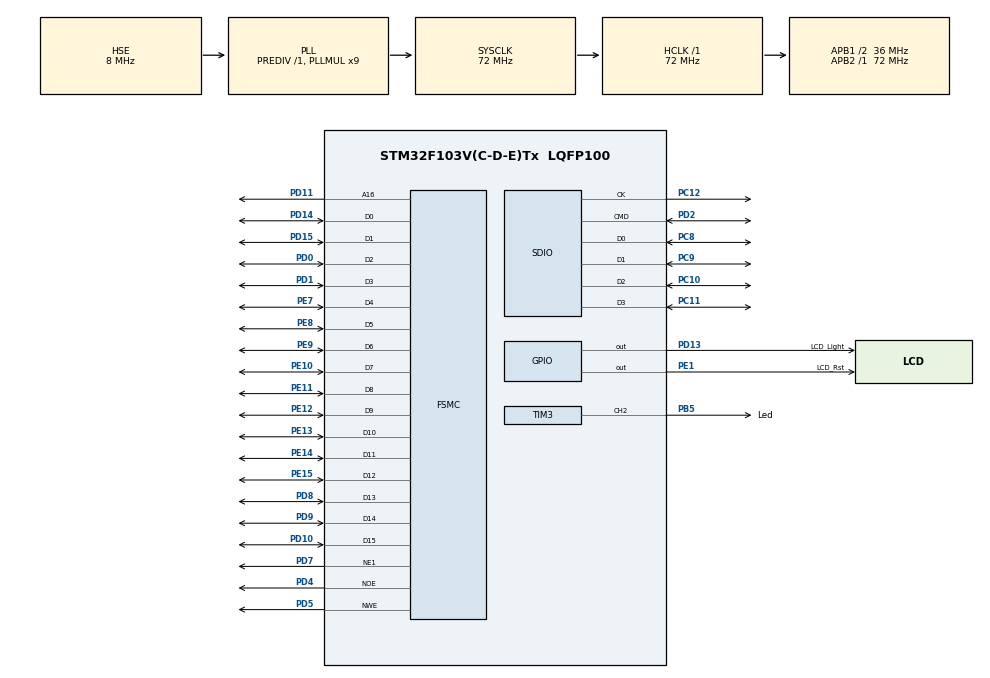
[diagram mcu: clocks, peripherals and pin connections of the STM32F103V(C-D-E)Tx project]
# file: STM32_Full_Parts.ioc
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FREERTOS.Tasks01=defaultTask,0,128,StartDefaultTask,Default,NULL
FREERTOS.configTOTAL_HEAP_SIZE=10000
FSMC.AddressSetupTime1=2
FSMC.BusTurnAroundDuration1=0
FSMC.DataSetupTime1=5
Mcu.Family=STM32F1
Mcu.Name=STM32F103V(C-D-E)Tx
Mcu.Package=LQFP100
NVIC.PriorityGroup=NVIC_PRIORITYGROUP_4
NVIC.TIM1_UP_IRQn=true\:0\:0\:false\:false\:true\:false\:false\:true
NVIC.TIM2_IRQn=true\:5\:0\:false\:false\:true\:true\:true\:true
NVIC.TIM4_IRQn=true\:5\:0\:false\:false\:true\:true\:true\:true
NVIC.TIM5_IRQn=true\:5\:0\:false\:false\:true\:true\:true\:true
NVIC.TimeBase=TIM1_UP_IRQn
NVIC.TimeBaseIP=TIM1
OSC_IN.Mode=HSE-External-Oscillator
OSC_IN.Signal=RCC_OSC_IN
OSC_OUT.Mode=HSE-External-Oscillator
OSC_OUT.Signal=RCC_OSC_OUT
PB5.GPIO_Label=Led
PB5.GPIO_Speed=GPIO_SPEED_FREQ_HIGH
PB5.Signal=S_TIM3_CH2
PC10.Mode=SD_4_bits_Wide_bus
PC10.Signal=SDIO_D2
PC11.Mode=SD_4_bits_Wide_bus
PC11.Signal=SDIO_D3
PC12.Mode=SD_4_bits_Wide_bus
PC12.Signal=SDIO_CK
PC14-OSC32_IN.Mode=LSE-External-Oscillator
PC14-OSC32_IN.Signal=RCC_OSC32_IN
PC15-OSC32_OUT.Mode=LSE-External-Oscillator
PC15-OSC32_OUT.Signal=RCC_OSC32_OUT
PC8.Mode=SD_4_bits_Wide_bus
PC8.Signal=SDIO_D0
PC9.Mode=SD_4_bits_Wide_bus
PC9.Signal=SDIO_D1
PD0.Mode=16b-d1
PD0.Signal=FSMC_D2
PD1.Mode=16b-d1
PD1.Signal=FSMC_D3
PD10.Mode=16b-d1
PD10.Signal=FSMC_D15
PD11.Mode=A16_1
PD11.Signal=FSMC_A16
PD13.GPIO_Label=LCD_Light
PD13.GPIO_Speed=GPIO_SPEED_FREQ_HIGH
PD13.Signal=GPIO_Output
PD14.Mode=16b-d1
PD14.Signal=FSMC_D0
PD15.Mode=16b-d1
PD15.Signal=FSMC_D1
PD2.Mode=SD_4_bits_Wide_bus
PD2.Signal=SDIO_CMD
PD4.Mode=Lcd1
PD4.Signal=FSMC_NOE
PD5.Mode=Lcd1
PD5.Signal=FSMC_NWE
PD7.Mode=NorPsramChipSelect1_1
PD7.Signal=FSMC_NE1
PD8.Mode=16b-d1
PD8.Signal=FSMC_D13
PD9.Mode=16b-d1
PD9.Signal=FSMC_D14
PE1.GPIO_Label=LCD_Rst
PE1.Signal=GPIO_Output
PE10.Mode=16b-d1
PE10.Signal=FSMC_D7
PE11.Mode=16b-d1
PE11.Signal=FSMC_D8
PE12.Mode=16b-d1
PE12.Signal=FSMC_D9
PE13.Mode=16b-d1
PE13.Signal=FSMC_D10
PE14.Mode=16b-d1
PE14.Signal=FSMC_D11
PE15.Mode=16b-d1
PE15.Signal=FSMC_D12
PE7.Mode=16b-d1
PE7.Signal=FSMC_D4
PE8.Mode=16b-d1
PE8.Signal=FSMC_D5
PE9.Mode=16b-d1
PE9.Signal=FSMC_D6
ProjectManager.HeapSize=0x2000
ProjectManager.StackSize=0x4000
ProjectManager.TargetToolchain=Makefile
RCC.AHBFreq_Value=72000000
RCC.APB1CLKDivider=RCC_HCLK_DIV2
RCC.APB1Freq_Value=36000000
RCC.APB1TimFreq_Value=72000000
RCC.APB2Freq_Value=72000000
RCC.APB2TimFreq_Value=72000000
RCC.HCLKFreq_Value=72000000
RCC.PLLMUL=RCC_PLL_MUL9
RCC.PLLSourceVirtual=RCC_PLLSOURCE_HSE
RCC.SYSCLKFreq_VALUE=72000000
RCC.SYSCLKSource=RCC_SYSCLKSOURCE_PLLCLK
RCC.USBFreq_Value=72000000
RTC.Date=18
RTC.Hours=16
RTC.Minutes=50
RTC.Month=RTC_MONTH_AUGUST
RTC.WeekDay=RTC_WEEKDAY_SATURDAY
RTC.Year=19
SDIO.ClockDiv=4
SH.S_TIM3_CH2.0=TIM3_CH2,PWM Generation2 CH2
TIM2.Period=2000-1
TIM2.Prescaler=36000-1
TIM3.Channel-PWM\ Generation2\ CH2=TIM_CHANNEL_2
TIM3.Period=2000-1
TIM3.Prescaler=36000-1
TIM4.Period=2000-1
TIM4.Prescaler=36000-1
TIM5.Period=2000-1
TIM5.Prescaler=36000-1
TIM8.Period=2000-1
TIM8.Prescaler=36000-1
VP_FATFS_VS_SDIO.Mode=SDIO
VP_FREERTOS_VS_CMSIS_V1.Mode=CMSIS_V1
VP_RTC_VS_RTC_Activate.Mode=RTC_Enabled
VP_RTC_VS_RTC_Calendar.Mode=RTC_Calendar
VP_SYS_VS_ND.Mode=No_Debug
VP_SYS_VS_tim1.Mode=TIM1
VP_TIM2_VS_ClockSourceINT.Mode=Internal
VP_TIM3_VS_ClockSourceINT.Mode=Internal
VP_TIM4_VS_ClockSourceINT.Mode=Internal
VP_TIM5_VS_ClockSourceINT.Mode=Internal
VP_TIM8_VS_ClockSourceINT.Mode=Internal
board=custom

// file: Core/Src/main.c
/* USER CODE BEGIN Header */
/**
  ******************************************************************************
  * @file           : main.c
  * @brief          : Main program body
  ******************************************************************************
  * @attention
  *
  * <h2><center>&copy; Copyright (c) 2019 STMicroelectronics.
  * All rights reserved.</center></h2>
  *
  * This software component is licensed by ST under BSD 3-Clause license,
  * the "License"; You may not use this file except in compliance with the
  * License. You may obtain a copy of the License at:
  *                        opensource.org/licenses/BSD-3-Clause
  *
  ******************************************************************************
  */
/* USER CODE END Header */

#include "main.h"
#include "cmsis_os.h"
#include "fatfs.h"
#include "rtc.h"
#include "sdio.h"
#include "tim.h"
#include "gpio.h"
#include "fsmc.h"

/* USER CODE BEGIN Includes */
#include "lcd.h"
/* USER CODE END Includes */

/* USER CODE BEGIN PV */
volatile uint32_t ulHighFrequencyTimerTicks = 0;
/* USER CODE END PV */

void SystemClock_Config(void);
void MX_FREERTOS_Init(void);

int main(void)
{
  /* USER CODE BEGIN 1 */
  SCB->VTOR = FLASH_BASE | 0X5000;
  /* USER CODE END 1 */

  /* MCU Configuration--------------------------------------------------------*/

  /* Reset of all peripherals, Initializes the Flash interface and the Systick. */
  HAL_Init();

  /* Configure the system clock */
  SystemClock_Config();

  /* Initialize all configured peripherals */
  MX_GPIO_Init();
  MX_FSMC_Init();
  MX_RTC_Init();
  MX_TIM2_Init();
  MX_TIM3_Init();
  MX_TIM4_Init();
  MX_TIM5_Init();
  MX_TIM8_Init();
  MX_SDIO_SD_Init();
  /* USER CODE BEGIN 2 */
  MX_SDIO_SD_Enable();
  LCD_Init();
  HAL_TIM_PWM_Start(&htim3, TIM_CHANNEL_2);
  HAL_TIM_Base_Start_IT(&htim5);

  cliShowSdInfo(NULL);
  cliShowSdFileInfo(NULL);
  /* USER CODE END 2 */

  /* Call init function for freertos objects (in freertos.c) */
  MX_FREERTOS_Init();

  /* Start scheduler */
  osKernelStart();

  /* We should never get here as control is now taken by the scheduler */

  /* Infinite loop */
  while (1)
  {

  }
}

void SystemClock_Config(void)
{
  RCC_OscInitTypeDef RCC_OscInitStruct = {0};
  RCC_ClkInitTypeDef RCC_ClkInitStruct = {0};
  RCC_PeriphCLKInitTypeDef PeriphClkInit = {0};

  /** Initializes the CPU, AHB and APB busses clocks
  */
  RCC_OscInitStruct.OscillatorType = RCC_OSCILLATORTYPE_LSI|RCC_OSCILLATORTYPE_HSE;
  RCC_OscInitStruct.HSEState = RCC_HSE_ON;
  RCC_OscInitStruct.HSEPredivValue = RCC_HSE_PREDIV_DIV1;
  RCC_OscInitStruct.HSIState = RCC_HSI_ON;
  RCC_OscInitStruct.LSIState = RCC_LSI_ON;
  RCC_OscInitStruct.PLL.PLLState = RCC_PLL_ON;
  RCC_OscInitStruct.PLL.PLLSource = RCC_PLLSOURCE_HSE;
  RCC_OscInitStruct.PLL.PLLMUL = RCC_PLL_MUL9;
  if (HAL_RCC_OscConfig(&RCC_OscInitStruct) != HAL_OK)
  {
    Error_Handler();
  }
  /** Initializes the CPU, AHB and APB busses clocks
  */
  RCC_ClkInitStruct.ClockType = RCC_CLOCKTYPE_HCLK|RCC_CLOCKTYPE_SYSCLK
                              |RCC_CLOCKTYPE_PCLK1|RCC_CLOCKTYPE_PCLK2;
  RCC_ClkInitStruct.SYSCLKSource = RCC_SYSCLKSOURCE_PLLCLK;
  RCC_ClkInitStruct.AHBCLKDivider = RCC_SYSCLK_DIV1;
  RCC_ClkInitStruct.APB1CLKDivider = RCC_HCLK_DIV2;
  RCC_ClkInitStruct.APB2CLKDivider = RCC_HCLK_DIV1;

  if (HAL_RCC_ClockConfig(&RCC_ClkInitStruct, FLASH_LATENCY_2) != HAL_OK)
  {
    Error_Handler();
  }
  PeriphClkInit.PeriphClockSelection = RCC_PERIPHCLK_RTC;
  PeriphClkInit.RTCClockSelection = RCC_RTCCLKSOURCE_LSI;
  if (HAL_RCCEx_PeriphCLKConfig(&PeriphClkInit) != HAL_OK)
  {
    Error_Handler();
  }
}

void HAL_TIM_PeriodElapsedCallback(TIM_HandleTypeDef *htim)
{
  if (htim->Instance == TIM1) {
    HAL_IncTick();
  }
  /* USER CODE BEGIN Callback 1 */
  if (htim->Instance == TIM5) {
    ulHighFrequencyTimerTicks++;
  }
  /* USER CODE END Callback 1 */
}

void Error_Handler(void)
{
}

/************************ (C) COPYRIGHT STMicroelectronics *****END OF FILE****/

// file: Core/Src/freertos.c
/* USER CODE BEGIN Header */
/**
  ******************************************************************************
  * File Name          : freertos.c
  * Description        : Code for freertos applications
  ******************************************************************************
  * @attention
  *
  * <h2><center>&copy; Copyright (c) 2019 STMicroelectronics.
  * All rights reserved.</center></h2>
  *
  * This software component is licensed by ST under Ultimate Liberty license
  * SLA0044, the "License"; You may not use this file except in compliance with
  * the License. You may obtain a copy of the License at:
  *                             www.st.com/SLA0044
  *
  ******************************************************************************
  */
/* USER CODE END Header */

#include "FreeRTOS.h"
#include "task.h"
#include "main.h"
#include "cmsis_os.h"

osThreadId defaultTaskHandle;

void StartDefaultTask(void const * argument);

extern void MX_FATFS_Init(void);
void MX_FREERTOS_Init(void); /* (MISRA C 2004 rule 8.1) */

void MX_FREERTOS_Init(void) {

  /* Create the thread(s) */
  /* definition and creation of defaultTask */
  osThreadDef(defaultTask, StartDefaultTask, osPriorityNormal, 0, 128);
  defaultTaskHandle = osThreadCreate(osThread(defaultTask), NULL);

}

void StartDefaultTask(void const * argument)
{

  /* init code for FATFS */
  MX_FATFS_Init();

  for(;;)
  {
    osDelay(1);
  }
}

/************************ (C) COPYRIGHT STMicroelectronics *****END OF FILE****/
